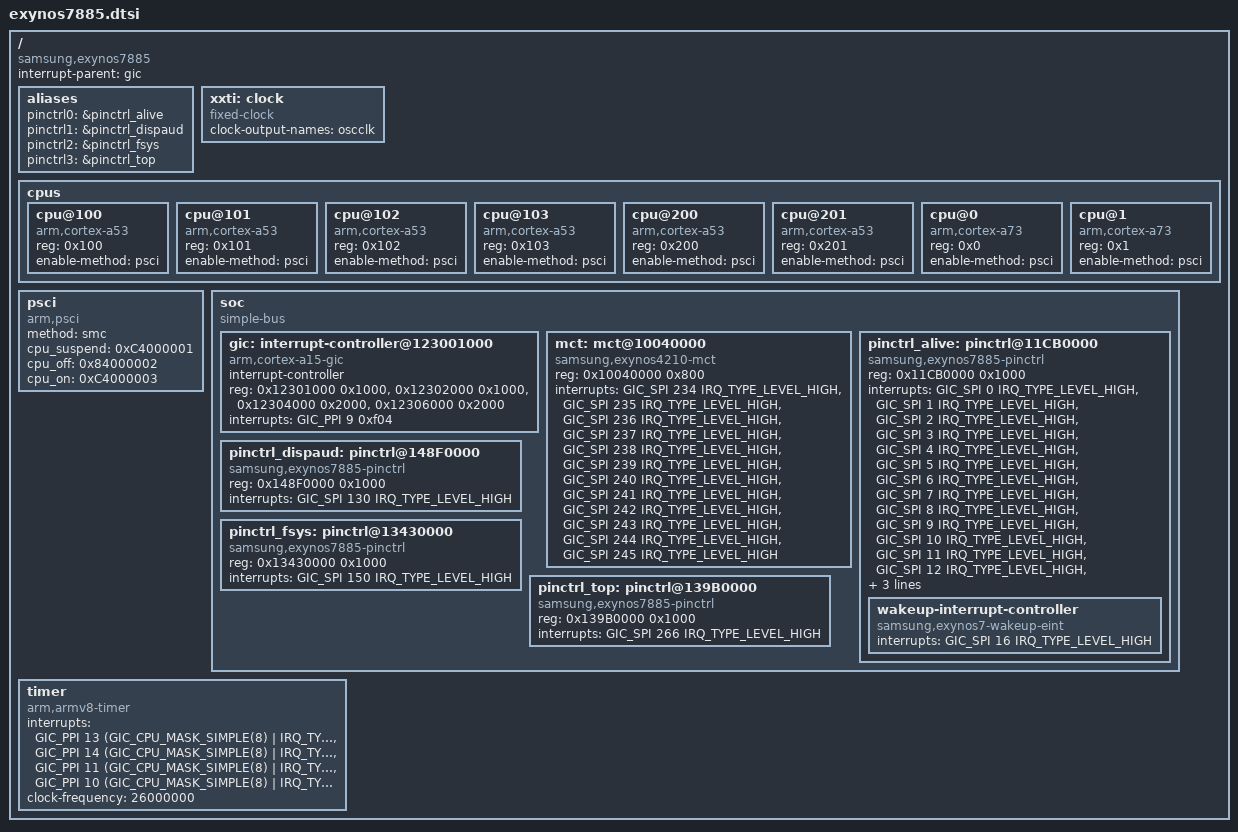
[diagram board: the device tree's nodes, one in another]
// SPDX-License-Identifier: BSD-3-Clause
/*
 * Copyright (c) 2020, Dávid Virág <virag.david003@gmail.com>
 * Copyright (C) 2020, Ivaylo Ivanov <ivo.ivanov@null.net>
 */

/dts-v1/;
#include <dt-bindings/interrupt-controller/arm-gic.h>

/ {
	compatible = "samsung,exynos7885";
	#address-cells = <2>;
	#size-cells = <2>;

	interrupt-parent = <&gic>;

	aliases {
		pinctrl0 = &pinctrl_alive;
		pinctrl1 = &pinctrl_dispaud;
		pinctrl2 = &pinctrl_fsys;
		pinctrl3 = &pinctrl_top;
	};

	xxti: clock {
		/* XXTI */
		compatible = "fixed-clock";
		clock-output-names = "oscclk";
		#clock-cells = <0>;
	};

	cpus {
		#address-cells = <1>;
		#size-cells = <0>;

		cpu@100 {
			device_type = "cpu";
			compatible = "arm,cortex-a53", "arm,armv8";
			reg = <0x100>;
			enable-method = "psci";
		};

		cpu@101 {
			device_type = "cpu";
			compatible = "arm,cortex-a53", "arm,armv8";
			reg = <0x101>;
			enable-method = "psci";
		};

		cpu@102 {
			device_type = "cpu";
			compatible = "arm,cortex-a53", "arm,armv8";
			reg = <0x102>;
			enable-method = "psci";
		};

		cpu@103 {
			device_type = "cpu";
			compatible = "arm,cortex-a53", "arm,armv8";
			reg = <0x103>;
			enable-method = "psci";
		};

		cpu@200 {
			device_type = "cpu";
			compatible = "arm,cortex-a53", "arm,armv8";
			reg = <0x200>;
			enable-method = "psci";
		};

		cpu@201 {
			device_type = "cpu";
			compatible = "arm,cortex-a53", "arm,armv8";
			reg = <0x201>;
			enable-method = "psci";
		};

		cpu@0 {
			device_type = "cpu";
			compatible = "arm,cortex-a73", "arm,armv8";
			reg = <0x0>;
			enable-method = "psci";
		};

		cpu@1 {
			device_type = "cpu";
			compatible = "arm,cortex-a73", "arm,armv8";
			reg = <0x1>;
			enable-method = "psci";
		};
	};

	psci {
		compatible = "arm,psci";
		method = "smc";
		cpu_suspend = <0xC4000001>;
		cpu_off = <0x84000002>;
		cpu_on = <0xC4000003>;
	};

	soc: soc {
		compatible = "simple-bus";
		#address-cells = <1>;
		#size-cells = <1>;
		ranges = <0 0 0 0x18000000>;

		gic: interrupt-controller@123001000 {
			compatible = "arm,cortex-a15-gic";
			#interrupt-cells = <3>;
			interrupt-controller;
			reg = <0x12301000 0x1000>,
			      <0x12302000 0x1000>,
			      <0x12304000 0x2000>,
			      <0x12306000 0x2000>;
			interrupts = <GIC_PPI 9 0xf04>;
		};

		mct: mct@10040000 {
			compatible = "samsung,exynos4210-mct";
			reg = <0x10040000 0x800>;
			interrupts = <GIC_SPI 234 IRQ_TYPE_LEVEL_HIGH>,
				<GIC_SPI 235 IRQ_TYPE_LEVEL_HIGH>,
				<GIC_SPI 236 IRQ_TYPE_LEVEL_HIGH>,
				<GIC_SPI 237 IRQ_TYPE_LEVEL_HIGH>,
				<GIC_SPI 238 IRQ_TYPE_LEVEL_HIGH>,
				<GIC_SPI 239 IRQ_TYPE_LEVEL_HIGH>,
				<GIC_SPI 240 IRQ_TYPE_LEVEL_HIGH>,
				<GIC_SPI 241 IRQ_TYPE_LEVEL_HIGH>,
				<GIC_SPI 242 IRQ_TYPE_LEVEL_HIGH>,
				<GIC_SPI 243 IRQ_TYPE_LEVEL_HIGH>,
				<GIC_SPI 244 IRQ_TYPE_LEVEL_HIGH>,
				<GIC_SPI 245 IRQ_TYPE_LEVEL_HIGH>;

			// TODO clocks
			//clocks = <&xxti>, <&cmu_peris CLK_PCLK_MCT>;
			//clock-names = "fin_pll", "mct";
		};

		pinctrl_alive: pinctrl@11CB0000 {
			compatible = "samsung,exynos7885-pinctrl";
			reg = <0x11CB0000 0x1000>;
			interrupts = <GIC_SPI 0 IRQ_TYPE_LEVEL_HIGH>,
				     <GIC_SPI 1 IRQ_TYPE_LEVEL_HIGH>,
				     <GIC_SPI 2 IRQ_TYPE_LEVEL_HIGH>,
				     <GIC_SPI 3 IRQ_TYPE_LEVEL_HIGH>,
				     <GIC_SPI 4 IRQ_TYPE_LEVEL_HIGH>,
				     <GIC_SPI 5 IRQ_TYPE_LEVEL_HIGH>,
				     <GIC_SPI 6 IRQ_TYPE_LEVEL_HIGH>,
				     <GIC_SPI 7 IRQ_TYPE_LEVEL_HIGH>,
				     <GIC_SPI 8 IRQ_TYPE_LEVEL_HIGH>,
				     <GIC_SPI 9 IRQ_TYPE_LEVEL_HIGH>,
				     <GIC_SPI 10 IRQ_TYPE_LEVEL_HIGH>,
				     <GIC_SPI 11 IRQ_TYPE_LEVEL_HIGH>,
				     <GIC_SPI 12 IRQ_TYPE_LEVEL_HIGH>,
				     <GIC_SPI 13 IRQ_TYPE_LEVEL_HIGH>,
				     <GIC_SPI 14 IRQ_TYPE_LEVEL_HIGH>,
				     <GIC_SPI 15 IRQ_TYPE_LEVEL_HIGH>;
			wakeup-interrupt-controller {
				compatible = "samsung,exynos7-wakeup-eint";
				interrupts = <GIC_SPI 16 IRQ_TYPE_LEVEL_HIGH>;
			};
		};

		pinctrl_dispaud: pinctrl@148F0000 {
			compatible = "samsung,exynos7885-pinctrl";
			reg = <0x148F0000 0x1000>;
			interrupts = <GIC_SPI 130 IRQ_TYPE_LEVEL_HIGH>;
		};

		pinctrl_fsys: pinctrl@13430000 {
			compatible = "samsung,exynos7885-pinctrl";
			reg = <0x13430000 0x1000>;
			interrupts = <GIC_SPI 150 IRQ_TYPE_LEVEL_HIGH>;
		};

		pinctrl_top: pinctrl@139B0000 {
			compatible = "samsung,exynos7885-pinctrl";
			reg = <0x139B0000 0x1000>;
			interrupts = <GIC_SPI 266 IRQ_TYPE_LEVEL_HIGH>;
		};
	};

	timer: timer {
		compatible = "arm,armv8-timer";
		interrupts = <GIC_PPI 13
				(GIC_CPU_MASK_SIMPLE(8) | IRQ_TYPE_LEVEL_HIGH)>,
			<GIC_PPI 14
				(GIC_CPU_MASK_SIMPLE(8) | IRQ_TYPE_LEVEL_HIGH)>,
			<GIC_PPI 11
				(GIC_CPU_MASK_SIMPLE(8) | IRQ_TYPE_LEVEL_HIGH)>,
			<GIC_PPI 10
				(GIC_CPU_MASK_SIMPLE(8) | IRQ_TYPE_LEVEL_HIGH)>;
		clock-frequency = <26000000>;
	};
};

#include "exynos7885-pinctrl.dtsi"
